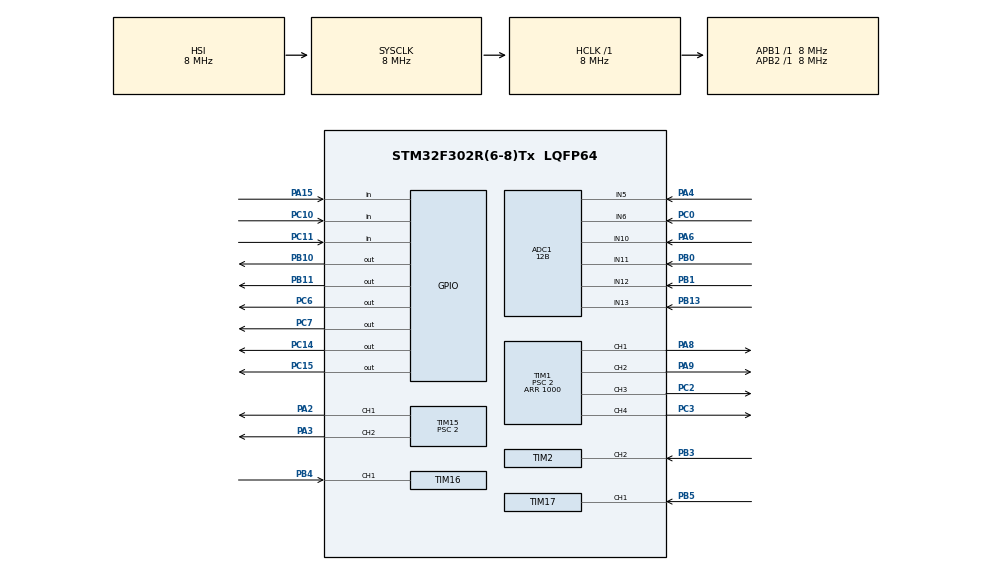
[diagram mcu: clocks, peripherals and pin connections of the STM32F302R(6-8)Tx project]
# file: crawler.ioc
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ADC1.Channel-0\#ChannelRegularConversion=ADC_CHANNEL_10
ADC1.Channel-10\#ChannelRegularConversion=ADC_CHANNEL_5
ADC1.Channel-11\#ChannelRegularConversion=ADC_CHANNEL_11
ADC1.Channel-12\#ChannelRegularConversion=ADC_CHANNEL_12
ADC1.Channel-13\#ChannelRegularConversion=ADC_CHANNEL_5
ADC1.Channel-14\#ChannelRegularConversion=ADC_CHANNEL_6
ADC1.Channel-15\#ChannelRegularConversion=ADC_CHANNEL_13
ADC1.Channel-6\#ChannelRegularConversion=ADC_CHANNEL_5
ADC1.Channel-7\#ChannelRegularConversion=ADC_CHANNEL_5
ADC1.Channel-8\#ChannelRegularConversion=ADC_CHANNEL_5
ADC1.Channel-9\#ChannelRegularConversion=ADC_CHANNEL_5
ADC1.ClockPrescaler=ADC_CLOCK_SYNC_PCLK_DIV4
ADC1.ContinuousConvMode=ENABLE
ADC1.DMAContinuousRequests=DISABLE
ADC1.DataAlign=ADC_DATAALIGN_RIGHT
ADC1.DiscontinuousConvMode=DISABLE
ADC1.EOCSelection=ADC_EOC_SINGLE_CONV
ADC1.EnableAnalogWatchDog1=false
ADC1.EnableAnalogWatchDog2=false
ADC1.EnableAnalogWatchDog3=false
ADC1.EnableInjectedConversion=ENABLE
ADC1.EnableRegularConversion=ENABLE
ADC1.ExternalTrigConv=ADC_SOFTWARE_START
ADC1.ExternalTrigConvEdge=ADC_EXTERNALTRIGCONVEDGE_NONE
ADC1.InjNumberOfConversion=0
ADC1.LowPowerAutoWait=DISABLE
ADC1.NbrOfConversion=6
ADC1.NbrOfConversionFlag=1
ADC1.Offset-0\#ChannelRegularConversion=0
ADC1.Offset-10\#ChannelRegularConversion=0
ADC1.Offset-11\#ChannelRegularConversion=0
ADC1.Offset-12\#ChannelRegularConversion=0
ADC1.Offset-13\#ChannelRegularConversion=0
ADC1.Offset-14\#ChannelRegularConversion=0
ADC1.Offset-15\#ChannelRegularConversion=0
ADC1.Offset-6\#ChannelRegularConversion=0
ADC1.Offset-7\#ChannelRegularConversion=0
ADC1.Offset-8\#ChannelRegularConversion=0
ADC1.Offset-9\#ChannelRegularConversion=0
ADC1.OffsetNumber-0\#ChannelRegularConversion=ADC_OFFSET_NONE
ADC1.OffsetNumber-10\#ChannelRegularConversion=ADC_OFFSET_NONE
ADC1.OffsetNumber-11\#ChannelRegularConversion=ADC_OFFSET_NONE
ADC1.OffsetNumber-12\#ChannelRegularConversion=ADC_OFFSET_NONE
ADC1.OffsetNumber-13\#ChannelRegularConversion=ADC_OFFSET_NONE
ADC1.OffsetNumber-14\#ChannelRegularConversion=ADC_OFFSET_NONE
ADC1.OffsetNumber-15\#ChannelRegularConversion=ADC_OFFSET_NONE
ADC1.OffsetNumber-6\#ChannelRegularConversion=ADC_OFFSET_NONE
ADC1.OffsetNumber-7\#ChannelRegularConversion=ADC_OFFSET_NONE
ADC1.OffsetNumber-8\#ChannelRegularConversion=ADC_OFFSET_NONE
ADC1.OffsetNumber-9\#ChannelRegularConversion=ADC_OFFSET_NONE
ADC1.Overrun=ADC_OVR_DATA_OVERWRITTEN
ADC1.Rank-0\#ChannelRegularConversion=1
ADC1.Rank-10\#ChannelRegularConversion=6
ADC1.Rank-11\#ChannelRegularConversion=2
ADC1.Rank-12\#ChannelRegularConversion=3
ADC1.Rank-13\#ChannelRegularConversion=4
ADC1.Rank-14\#ChannelRegularConversion=5
ADC1.Rank-15\#ChannelRegularConversion=6
ADC1.Rank-6\#ChannelRegularConversion=2
ADC1.Rank-7\#ChannelRegularConversion=3
ADC1.Rank-8\#ChannelRegularConversion=4
ADC1.Rank-9\#ChannelRegularConversion=5
ADC1.Resolution=ADC_RESOLUTION_12B
ADC1.SamplingTime-0\#ChannelRegularConversion=ADC_SAMPLETIME_1CYCLE_5
ADC1.SamplingTime-10\#ChannelRegularConversion=ADC_SAMPLETIME_1CYCLE_5
ADC1.SamplingTime-11\#ChannelRegularConversion=ADC_SAMPLETIME_1CYCLE_5
ADC1.SamplingTime-12\#ChannelRegularConversion=ADC_SAMPLETIME_1CYCLE_5
ADC1.SamplingTime-13\#ChannelRegularConversion=ADC_SAMPLETIME_1CYCLE_5
ADC1.SamplingTime-14\#ChannelRegularConversion=ADC_SAMPLETIME_1CYCLE_5
ADC1.SamplingTime-15\#ChannelRegularConversion=ADC_SAMPLETIME_1CYCLE_5
ADC1.SamplingTime-6\#ChannelRegularConversion=ADC_SAMPLETIME_1CYCLE_5
ADC1.SamplingTime-7\#ChannelRegularConversion=ADC_SAMPLETIME_1CYCLE_5
ADC1.SamplingTime-8\#ChannelRegularConversion=ADC_SAMPLETIME_1CYCLE_5
ADC1.SamplingTime-9\#ChannelRegularConversion=ADC_SAMPLETIME_1CYCLE_5
ADC1.ScanConvMode=ADC_SCAN_ENABLE
ADC1.master=1
Dma.ADC1.0.Direction=DMA_PERIPH_TO_MEMORY
Dma.ADC1.0.Instance=DMA1_Channel1
Dma.ADC1.0.MemDataAlignment=DMA_MDATAALIGN_HALFWORD
Dma.ADC1.0.MemInc=DMA_MINC_ENABLE
Dma.ADC1.0.Mode=DMA_NORMAL
Dma.ADC1.0.PeriphDataAlignment=DMA_PDATAALIGN_HALFWORD
Dma.ADC1.0.PeriphInc=DMA_PINC_DISABLE
Dma.ADC1.0.Priority=DMA_PRIORITY_LOW
Dma.Request0=ADC1
Mcu.Family=STM32F3
Mcu.Name=STM32F302R(6-8)Tx
Mcu.Package=LQFP64
NVIC.DMA1_Channel1_IRQn=true\:0\:0\:false\:false\:true\:false
NVIC.PriorityGroup=NVIC_PRIORITYGROUP_4
NVIC.TIM1_TRG_COM_TIM17_IRQn=true\:0\:0\:false\:false\:true\:true
NVIC.TIM1_UP_TIM16_IRQn=true\:0\:0\:false\:false\:true\:true
NVIC.TIM2_IRQn=true\:0\:0\:false\:false\:true\:true
PA15.Signal=GPIO_Input
PA2.Signal=S_TIM15_CH1
PA3.Signal=S_TIM15_CH2
PA4.Mode=IN5-Single-Ended
PA4.Signal=ADC1_IN5
PA6.Signal=ADCx_IN10
PA8.Signal=S_TIM1_CH1
PA9.Signal=S_TIM1_CH2
PB0.Mode=IN11-Single-Ended
PB0.Signal=ADC1_IN11
PB1.Mode=IN12-Single-Ended
PB1.Signal=ADC1_IN12
PB10.Signal=GPIO_Output
PB11.Signal=GPIO_Output
PB13.Mode=IN13-Single-Ended
PB13.Signal=ADC1_IN13
PB3.Signal=S_TIM2_CH2
PB4.Signal=S_TIM16_CH1
PB5.Signal=S_TIM17_CH1
PC0.Signal=ADCx_IN6
PC10.Signal=GPIO_Input
PC11.Signal=GPIO_Input
PC14\ -\ OSC32_IN.Signal=GPIO_Output
PC15\ -\ OSC32_OUT.Signal=GPIO_Output
PC2.Signal=S_TIM1_CH3
PC3.Signal=S_TIM1_CH4
PC6.Signal=GPIO_Output
PC7.Signal=GPIO_Output
PF0-OSC_IN.Mode=HSE-External-Oscillator
PF0-OSC_IN.Signal=RCC_OSC_IN
PF1-OSC_OUT.Mode=HSE-External-Oscillator
PF1-OSC_OUT.Signal=RCC_OSC_OUT
ProjectManager.HeapSize=0x200
ProjectManager.StackSize=0x400
ProjectManager.TargetToolchain=TrueSTUDIO
RCC.AHBFreq_Value=8000000
RCC.APB1Freq_Value=8000000
RCC.APB2Freq_Value=8000000
RCC.CortexFreq_Value=8000000
RCC.HSE_VALUE=8000000
RCC.HSI_VALUE=8000000
RCC.LSE_VALUE=32768
RCC.PLLMUL=RCC_PLL_MUL4
RCC.SYSCLKFreq_VALUE=8000000
RCC.USBFreq_Value=16000000
SH.ADCx_IN10.0=ADC1_IN10,IN10-Single-Ended
SH.ADCx_IN6.0=ADC1_IN6,IN6-Single-Ended
SH.S_TIM15_CH1.0=TIM15_CH1,PWM Generation1 CH1
SH.S_TIM15_CH2.0=TIM15_CH2,PWM Generation2 CH2
SH.S_TIM16_CH1.0=TIM16_CH1,Input_Capture1_from_TI1
SH.S_TIM17_CH1.0=TIM17_CH1,Input_Capture1_from_TI1
SH.S_TIM1_CH1.0=TIM1_CH1,PWM Generation1 CH1
SH.S_TIM1_CH2.0=TIM1_CH2,PWM Generation2 CH2
SH.S_TIM1_CH3.0=TIM1_CH3,PWM Generation3 CH3
SH.S_TIM1_CH4.0=TIM1_CH4,PWM Generation4 CH4
SH.S_TIM2_CH2.0=TIM2_CH2,Input_Capture2_from_TI2
TIM1.Channel-PWM\ Generation1\ CH1=TIM_CHANNEL_1
TIM1.Channel-PWM\ Generation2\ CH2=TIM_CHANNEL_2
TIM1.Channel-PWM\ Generation3\ CH3=TIM_CHANNEL_3
TIM1.Channel-PWM\ Generation4\ CH4=TIM_CHANNEL_4
TIM1.Period=1000
TIM1.Prescaler=2
TIM15.Channel-PWM\ Generation1\ CH1=TIM_CHANNEL_1
TIM15.Channel-PWM\ Generation2\ CH2=TIM_CHANNEL_2
TIM15.Period=1000
TIM15.Prescaler=2
TIM16.Channel=TIM_CHANNEL_1
TIM16.Period=0xFFFF
TIM16.Prescaler=10
TIM17.Channel=TIM_CHANNEL_1
TIM17.Period=0xFFFF
TIM17.Prescaler=10
TIM2.Channel-Input_Capture2_from_TI2=TIM_CHANNEL_2
TIM2.ICFilter_CH2=15
TIM2.Period=0xFFFF
TIM2.Prescaler=10
VP_TIM16_VS_ClockSourceINT.Mode=Enable_Timer
VP_TIM17_VS_ClockSourceINT.Mode=Enable_Timer
VP_TIM1_VS_ClockSourceINT.Mode=Internal
VP_TIM2_VS_ClockSourceINT.Mode=Internal
board=crawler

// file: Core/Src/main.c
/**
  ******************************************************************************
  * @file           : main.c
  * @brief          : Main program body
  ******************************************************************************
  ** This notice applies to any and all portions of this file
  * that are not between comment pairs USER CODE BEGIN and
  * USER CODE END. Other portions of this file, whether
  * inserted by the user or by software development tools
  * are owned by their respective copyright owners.
  *
  * COPYRIGHT(c) 2019 STMicroelectronics
  *
  * Redistribution and use in source and binary forms, with or without modification,
  * are permitted provided that the following conditions are met:
  *   1. Redistributions of source code must retain the above copyright notice,
  *      this list of conditions and the following disclaimer.
  *   2. Redistributions in binary form must reproduce the above copyright notice,
  *      this list of conditions and the following disclaimer in the documentation
  *      and/or other materials provided with the distribution.
  *   3. Neither the name of STMicroelectronics nor the names of its contributors
  *      may be used to endorse or promote products derived from this software
  *      without specific prior written permission.
  *
  * THIS SOFTWARE IS PROVIDED BY THE COPYRIGHT HOLDERS AND CONTRIBUTORS "AS IS"
  * AND ANY EXPRESS OR IMPLIED WARRANTIES, INCLUDING, BUT NOT LIMITED TO, THE
  * IMPLIED WARRANTIES OF MERCHANTABILITY AND FITNESS FOR A PARTICULAR PURPOSE ARE
  * DISCLAIMED. IN NO EVENT SHALL THE COPYRIGHT HOLDER OR CONTRIBUTORS BE LIABLE
  * FOR ANY DIRECT, INDIRECT, INCIDENTAL, SPECIAL, EXEMPLARY, OR CONSEQUENTIAL
  * DAMAGES (INCLUDING, BUT NOT LIMITED TO, PROCUREMENT OF SUBSTITUTE GOODS OR
  * SERVICES; LOSS OF USE, DATA, OR PROFITS; OR BUSINESS INTERRUPTION) HOWEVER
  * CAUSED AND ON ANY THEORY OF LIABILITY, WHETHER IN CONTRACT, STRICT LIABILITY,
  * OR TORT (INCLUDING NEGLIGENCE OR OTHERWISE) ARISING IN ANY WAY OUT OF THE USE
  * OF THIS SOFTWARE, EVEN IF ADVISED OF THE POSSIBILITY OF SUCH DAMAGE.
  *
  ******************************************************************************
  */
#include "main.h"
#include "stm32f3xx_hal.h"
#include <ADC_libF3.h>
#include <ENKPWM_libF3.h>
#include <PWM_libF3.h>

ADC_HandleTypeDef hadc1;
DMA_HandleTypeDef hdma_adc1;

TIM_HandleTypeDef htim1;
TIM_HandleTypeDef htim2;
TIM_HandleTypeDef htim15;
TIM_HandleTypeDef htim16;
TIM_HandleTypeDef htim17;

/* USER CODE BEGIN PV */
/* Private variables ---------------------------------------------------------*/
volatile uint32_t DMA_Stream[6];
volatile uint32_t Current[3];
/* USER CODE END PV */

void SystemClock_Config(void);
static void MX_GPIO_Init(void);
static void MX_DMA_Init(void);
static void MX_TIM1_Init(void);
static void MX_TIM15_Init(void);
static void MX_TIM2_Init(void);
static void MX_TIM16_Init(void);
static void MX_TIM17_Init(void);
static void MX_ADC1_Init(void);

void HAL_TIM_MspPostInit(TIM_HandleTypeDef *htim);

/* USER CODE BEGIN PFP */
/* Private function prototypes -----------------------------------------------*/

/* USER CODE END PFP */

int main(void)
{

  /* MCU Configuration----------------------------------------------------------*/

  /* Reset of all peripherals, Initializes the Flash interface and the Systick. */
  HAL_Init();

  /* Configure the system clock */
  SystemClock_Config();

  /* Initialize all configured peripherals */
  MX_GPIO_Init();
  MX_DMA_Init();
  MX_TIM1_Init();
  MX_TIM15_Init();
  MX_TIM2_Init();
  MX_TIM16_Init();
  MX_TIM17_Init();
  MX_ADC1_Init();

  HAL_ADC_Start_DMA(&hadc1, DMA_Stream, 6);
  /* USER CODE BEGIN 2 */
  PWM_Init();
  ENK_Init();
  StartMotors();
  SetPWM(-300);
  /* USER CODE END 2 */

  /* Infinite loop */
  /* USER CODE BEGIN WHILE */
  while (1)
  {
	  frequency_ret(abs_period_motor_1, abs_period_motor_2, abs_period_motor_3);

  /* USER CODE END WHILE */

  }

}

void SystemClock_Config(void)
{

  RCC_OscInitTypeDef RCC_OscInitStruct;
  RCC_ClkInitTypeDef RCC_ClkInitStruct;
  RCC_PeriphCLKInitTypeDef PeriphClkInit;

    /**Initializes the CPU, AHB and APB busses clocks
    */
  RCC_OscInitStruct.OscillatorType = RCC_OSCILLATORTYPE_HSI;
  RCC_OscInitStruct.HSIState = RCC_HSI_ON;
  RCC_OscInitStruct.HSICalibrationValue = 16;
  RCC_OscInitStruct.PLL.PLLState = RCC_PLL_NONE;
  if (HAL_RCC_OscConfig(&RCC_OscInitStruct) != HAL_OK)
  {
    _Error_Handler(__FILE__, __LINE__);
  }

    /**Initializes the CPU, AHB and APB busses clocks
    */
  RCC_ClkInitStruct.ClockType = RCC_CLOCKTYPE_HCLK|RCC_CLOCKTYPE_SYSCLK
                              |RCC_CLOCKTYPE_PCLK1|RCC_CLOCKTYPE_PCLK2;
  RCC_ClkInitStruct.SYSCLKSource = RCC_SYSCLKSOURCE_HSI;
  RCC_ClkInitStruct.AHBCLKDivider = RCC_SYSCLK_DIV1;
  RCC_ClkInitStruct.APB1CLKDivider = RCC_HCLK_DIV1;
  RCC_ClkInitStruct.APB2CLKDivider = RCC_HCLK_DIV1;

  if (HAL_RCC_ClockConfig(&RCC_ClkInitStruct, FLASH_LATENCY_0) != HAL_OK)
  {
    _Error_Handler(__FILE__, __LINE__);
  }

  PeriphClkInit.PeriphClockSelection = RCC_PERIPHCLK_TIM1|RCC_PERIPHCLK_TIM15
                              |RCC_PERIPHCLK_TIM16|RCC_PERIPHCLK_TIM17;
  PeriphClkInit.Tim1ClockSelection = RCC_TIM1CLK_HCLK;
  PeriphClkInit.Tim15ClockSelection = RCC_TIM15CLK_HCLK;
  PeriphClkInit.Tim16ClockSelection = RCC_TIM16CLK_HCLK;
  PeriphClkInit.Tim17ClockSelection = RCC_TIM17CLK_HCLK;
  if (HAL_RCCEx_PeriphCLKConfig(&PeriphClkInit) != HAL_OK)
  {
    _Error_Handler(__FILE__, __LINE__);
  }

    /**Configure the Systick interrupt time
    */
  HAL_SYSTICK_Config(HAL_RCC_GetHCLKFreq()/1000);

    /**Configure the Systick
    */
  HAL_SYSTICK_CLKSourceConfig(SYSTICK_CLKSOURCE_HCLK);

  /* SysTick_IRQn interrupt configuration */
  HAL_NVIC_SetPriority(SysTick_IRQn, 0, 0);
}

/* ADC1 init function */
static void MX_ADC1_Init(void)
{

  ADC_ChannelConfTypeDef sConfig;

    /**Common config
    */
  hadc1.Instance = ADC1;
  hadc1.Init.ClockPrescaler = ADC_CLOCK_SYNC_PCLK_DIV4;
  hadc1.Init.Resolution = ADC_RESOLUTION_12B;
  hadc1.Init.ScanConvMode = ADC_SCAN_ENABLE;
  hadc1.Init.ContinuousConvMode = ENABLE;
  hadc1.Init.DiscontinuousConvMode = DISABLE;
  hadc1.Init.ExternalTrigConvEdge = ADC_EXTERNALTRIGCONVEDGE_NONE;
  hadc1.Init.ExternalTrigConv = ADC_SOFTWARE_START;
  hadc1.Init.DataAlign = ADC_DATAALIGN_RIGHT;
  hadc1.Init.NbrOfConversion = 6;
  hadc1.Init.DMAContinuousRequests = DISABLE;
  hadc1.Init.EOCSelection = ADC_EOC_SINGLE_CONV;
  hadc1.Init.LowPowerAutoWait = DISABLE;
  hadc1.Init.Overrun = ADC_OVR_DATA_OVERWRITTEN;
  if (HAL_ADC_Init(&hadc1) != HAL_OK)
  {
    _Error_Handler(__FILE__, __LINE__);
  }

    /**Configure Regular Channel
    */
  sConfig.Channel = ADC_CHANNEL_10;
  sConfig.Rank = ADC_REGULAR_RANK_1;
  sConfig.SingleDiff = ADC_SINGLE_ENDED;
  sConfig.SamplingTime = ADC_SAMPLETIME_1CYCLE_5;
  sConfig.OffsetNumber = ADC_OFFSET_NONE;
  sConfig.Offset = 0;
  if (HAL_ADC_ConfigChannel(&hadc1, &sConfig) != HAL_OK)
  {
    _Error_Handler(__FILE__, __LINE__);
  }

    /**Configure Regular Channel
    */
  sConfig.Channel = ADC_CHANNEL_11;
  sConfig.Rank = ADC_REGULAR_RANK_2;
  if (HAL_ADC_ConfigChannel(&hadc1, &sConfig) != HAL_OK)
  {
    _Error_Handler(__FILE__, __LINE__);
  }

    /**Configure Regular Channel
    */
  sConfig.Channel = ADC_CHANNEL_12;
  sConfig.Rank = ADC_REGULAR_RANK_3;
  if (HAL_ADC_ConfigChannel(&hadc1, &sConfig) != HAL_OK)
  {
    _Error_Handler(__FILE__, __LINE__);
  }

    /**Configure Regular Channel
    */
  sConfig.Channel = ADC_CHANNEL_5;
  sConfig.Rank = ADC_REGULAR_RANK_4;
  if (HAL_ADC_ConfigChannel(&hadc1, &sConfig) != HAL_OK)
  {
    _Error_Handler(__FILE__, __LINE__);
  }

    /**Configure Regular Channel
    */
  sConfig.Channel = ADC_CHANNEL_6;
  sConfig.Rank = ADC_REGULAR_RANK_5;
  if (HAL_ADC_ConfigChannel(&hadc1, &sConfig) != HAL_OK)
  {
    _Error_Handler(__FILE__, __LINE__);
  }

    /**Configure Regular Channel
    */
  sConfig.Channel = ADC_CHANNEL_13;
  sConfig.Rank = ADC_REGULAR_RANK_6;
  if (HAL_ADC_ConfigChannel(&hadc1, &sConfig) != HAL_OK)
  {
    _Error_Handler(__FILE__, __LINE__);
  }

}

/* TIM1 init function */
static void MX_TIM1_Init(void)
{

  TIM_ClockConfigTypeDef sClockSourceConfig;
  TIM_MasterConfigTypeDef sMasterConfig;
  TIM_OC_InitTypeDef sConfigOC;
  TIM_BreakDeadTimeConfigTypeDef sBreakDeadTimeConfig;

  htim1.Instance = TIM1;
  htim1.Init.Prescaler = 2;
  htim1.Init.CounterMode = TIM_COUNTERMODE_UP;
  htim1.Init.Period = 1000;
  htim1.Init.ClockDivision = TIM_CLOCKDIVISION_DIV1;
  htim1.Init.RepetitionCounter = 0;
  htim1.Init.AutoReloadPreload = TIM_AUTORELOAD_PRELOAD_DISABLE;
  if (HAL_TIM_Base_Init(&htim1) != HAL_OK)
  {
    _Error_Handler(__FILE__, __LINE__);
  }

  sClockSourceConfig.ClockSource = TIM_CLOCKSOURCE_INTERNAL;
  if (HAL_TIM_ConfigClockSource(&htim1, &sClockSourceConfig) != HAL_OK)
  {
    _Error_Handler(__FILE__, __LINE__);
  }

  if (HAL_TIM_PWM_Init(&htim1) != HAL_OK)
  {
    _Error_Handler(__FILE__, __LINE__);
  }

  sMasterConfig.MasterOutputTrigger = TIM_TRGO_RESET;
  sMasterConfig.MasterOutputTrigger2 = TIM_TRGO2_RESET;
  sMasterConfig.MasterSlaveMode = TIM_MASTERSLAVEMODE_DISABLE;
  if (HAL_TIMEx_MasterConfigSynchronization(&htim1, &sMasterConfig) != HAL_OK)
  {
    _Error_Handler(__FILE__, __LINE__);
  }

  sConfigOC.OCMode = TIM_OCMODE_PWM1;
  sConfigOC.Pulse = 0;
  sConfigOC.OCPolarity = TIM_OCPOLARITY_HIGH;
  sConfigOC.OCNPolarity = TIM_OCNPOLARITY_HIGH;
  sConfigOC.OCFastMode = TIM_OCFAST_DISABLE;
  sConfigOC.OCIdleState = TIM_OCIDLESTATE_RESET;
  sConfigOC.OCNIdleState = TIM_OCNIDLESTATE_RESET;
  if (HAL_TIM_PWM_ConfigChannel(&htim1, &sConfigOC, TIM_CHANNEL_1) != HAL_OK)
  {
    _Error_Handler(__FILE__, __LINE__);
  }

  if (HAL_TIM_PWM_ConfigChannel(&htim1, &sConfigOC, TIM_CHANNEL_2) != HAL_OK)
  {
    _Error_Handler(__FILE__, __LINE__);
  }

  if (HAL_TIM_PWM_ConfigChannel(&htim1, &sConfigOC, TIM_CHANNEL_3) != HAL_OK)
  {
    _Error_Handler(__FILE__, __LINE__);
  }

  if (HAL_TIM_PWM_ConfigChannel(&htim1, &sConfigOC, TIM_CHANNEL_4) != HAL_OK)
  {
    _Error_Handler(__FILE__, __LINE__);
  }

  sBreakDeadTimeConfig.OffStateRunMode = TIM_OSSR_DISABLE;
  sBreakDeadTimeConfig.OffStateIDLEMode = TIM_OSSI_DISABLE;
  sBreakDeadTimeConfig.LockLevel = TIM_LOCKLEVEL_OFF;
  sBreakDeadTimeConfig.DeadTime = 0;
  sBreakDeadTimeConfig.BreakState = TIM_BREAK_DISABLE;
  sBreakDeadTimeConfig.BreakPolarity = TIM_BREAKPOLARITY_HIGH;
  sBreakDeadTimeConfig.BreakFilter = 0;
  sBreakDeadTimeConfig.Break2State = TIM_BREAK2_DISABLE;
  sBreakDeadTimeConfig.Break2Polarity = TIM_BREAK2POLARITY_HIGH;
  sBreakDeadTimeConfig.Break2Filter = 0;
  sBreakDeadTimeConfig.AutomaticOutput = TIM_AUTOMATICOUTPUT_DISABLE;
  if (HAL_TIMEx_ConfigBreakDeadTime(&htim1, &sBreakDeadTimeConfig) != HAL_OK)
  {
    _Error_Handler(__FILE__, __LINE__);
  }

  HAL_TIM_MspPostInit(&htim1);

}

/* TIM2 init function */
static void MX_TIM2_Init(void)
{

  TIM_ClockConfigTypeDef sClockSourceConfig;
  TIM_MasterConfigTypeDef sMasterConfig;
  TIM_IC_InitTypeDef sConfigIC;

  htim2.Instance = TIM2;
  htim2.Init.Prescaler = 10;
  htim2.Init.CounterMode = TIM_COUNTERMODE_UP;
  htim2.Init.Period = 0xFFFF;
  htim2.Init.ClockDivision = TIM_CLOCKDIVISION_DIV1;
  htim2.Init.AutoReloadPreload = TIM_AUTORELOAD_PRELOAD_DISABLE;
  if (HAL_TIM_Base_Init(&htim2) != HAL_OK)
  {
    _Error_Handler(__FILE__, __LINE__);
  }

  sClockSourceConfig.ClockSource = TIM_CLOCKSOURCE_INTERNAL;
  if (HAL_TIM_ConfigClockSource(&htim2, &sClockSourceConfig) != HAL_OK)
  {
    _Error_Handler(__FILE__, __LINE__);
  }

  if (HAL_TIM_IC_Init(&htim2) != HAL_OK)
  {
    _Error_Handler(__FILE__, __LINE__);
  }

  sMasterConfig.MasterOutputTrigger = TIM_TRGO_RESET;
  sMasterConfig.MasterSlaveMode = TIM_MASTERSLAVEMODE_DISABLE;
  if (HAL_TIMEx_MasterConfigSynchronization(&htim2, &sMasterConfig) != HAL_OK)
  {
    _Error_Handler(__FILE__, __LINE__);
  }

  sConfigIC.ICPolarity = TIM_INPUTCHANNELPOLARITY_RISING;
  sConfigIC.ICSelection = TIM_ICSELECTION_DIRECTTI;
  sConfigIC.ICPrescaler = TIM_ICPSC_DIV1;
  sConfigIC.ICFilter = 15;
  if (HAL_TIM_IC_ConfigChannel(&htim2, &sConfigIC, TIM_CHANNEL_2) != HAL_OK)
  {
    _Error_Handler(__FILE__, __LINE__);
  }

}

/* TIM15 init function */
static void MX_TIM15_Init(void)
{

  TIM_MasterConfigTypeDef sMasterConfig;
  TIM_OC_InitTypeDef sConfigOC;
  TIM_BreakDeadTimeConfigTypeDef sBreakDeadTimeConfig;

  htim15.Instance = TIM15;
  htim15.Init.Prescaler = 2;
  htim15.Init.CounterMode = TIM_COUNTERMODE_UP;
  htim15.Init.Period = 1000;
  htim15.Init.ClockDivision = TIM_CLOCKDIVISION_DIV1;
  htim15.Init.RepetitionCounter = 0;
  htim15.Init.AutoReloadPreload = TIM_AUTORELOAD_PRELOAD_DISABLE;
  if (HAL_TIM_PWM_Init(&htim15) != HAL_OK)
  {
    _Error_Handler(__FILE__, __LINE__);
  }

  sMasterConfig.MasterOutputTrigger = TIM_TRGO_RESET;
  sMasterConfig.MasterSlaveMode = TIM_MASTERSLAVEMODE_DISABLE;
  if (HAL_TIMEx_MasterConfigSynchronization(&htim15, &sMasterConfig) != HAL_OK)
  {
    _Error_Handler(__FILE__, __LINE__);
  }

  sConfigOC.OCMode = TIM_OCMODE_PWM1;
  sConfigOC.Pulse = 0;
  sConfigOC.OCPolarity = TIM_OCPOLARITY_HIGH;
  sConfigOC.OCNPolarity = TIM_OCNPOLARITY_HIGH;
  sConfigOC.OCFastMode = TIM_OCFAST_DISABLE;
  sConfigOC.OCIdleState = TIM_OCIDLESTATE_RESET;
  sConfigOC.OCNIdleState = TIM_OCNIDLESTATE_RESET;
  if (HAL_TIM_PWM_ConfigChannel(&htim15, &sConfigOC, TIM_CHANNEL_1) != HAL_OK)
  {
    _Error_Handler(__FILE__, __LINE__);
  }

  if (HAL_TIM_PWM_ConfigChannel(&htim15, &sConfigOC, TIM_CHANNEL_2) != HAL_OK)
  {
    _Error_Handler(__FILE__, __LINE__);
  }

  sBreakDeadTimeConfig.OffStateRunMode = TIM_OSSR_DISABLE;
  sBreakDeadTimeConfig.OffStateIDLEMode = TIM_OSSI_DISABLE;
  sBreakDeadTimeConfig.LockLevel = TIM_LOCKLEVEL_OFF;
  sBreakDeadTimeConfig.DeadTime = 0;
  sBreakDeadTimeConfig.BreakState = TIM_BREAK_DISABLE;
  sBreakDeadTimeConfig.BreakPolarity = TIM_BREAKPOLARITY_HIGH;
  sBreakDeadTimeConfig.BreakFilter = 0;
  sBreakDeadTimeConfig.AutomaticOutput = TIM_AUTOMATICOUTPUT_DISABLE;
  if (HAL_TIMEx_ConfigBreakDeadTime(&htim15, &sBreakDeadTimeConfig) != HAL_OK)
  {
    _Error_Handler(__FILE__, __LINE__);
  }

  HAL_TIM_MspPostInit(&htim15);

}

/* TIM16 init function */
static void MX_TIM16_Init(void)
{

  TIM_IC_InitTypeDef sConfigIC;

  htim16.Instance = TIM16;
  htim16.Init.Prescaler = 10;
  htim16.Init.CounterMode = TIM_COUNTERMODE_UP;
  htim16.Init.Period = 0xFFFF;
  htim16.Init.ClockDivision = TIM_CLOCKDIVISION_DIV1;
  htim16.Init.RepetitionCounter = 0;
  htim16.Init.AutoReloadPreload = TIM_AUTORELOAD_PRELOAD_DISABLE;
  if (HAL_TIM_Base_Init(&htim16) != HAL_OK)
  {
    _Error_Handler(__FILE__, __LINE__);
  }

  if (HAL_TIM_IC_Init(&htim16) != HAL_OK)
  {
    _Error_Handler(__FILE__, __LINE__);
  }

  sConfigIC.ICPolarity = TIM_INPUTCHANNELPOLARITY_RISING;
  sConfigIC.ICSelection = TIM_ICSELECTION_DIRECTTI;
  sConfigIC.ICPrescaler = TIM_ICPSC_DIV1;
  sConfigIC.ICFilter = 0;
  if (HAL_TIM_IC_ConfigChannel(&htim16, &sConfigIC, TIM_CHANNEL_1) != HAL_OK)
  {
    _Error_Handler(__FILE__, __LINE__);
  }

}

/* TIM17 init function */
static void MX_TIM17_Init(void)
{

  TIM_IC_InitTypeDef sConfigIC;

  htim17.Instance = TIM17;
  htim17.Init.Prescaler = 10;
  htim17.Init.CounterMode = TIM_COUNTERMODE_UP;
  htim17.Init.Period = 0xFFFF;
  htim17.Init.ClockDivision = TIM_CLOCKDIVISION_DIV1;
  htim17.Init.RepetitionCounter = 0;
  htim17.Init.AutoReloadPreload = TIM_AUTORELOAD_PRELOAD_DISABLE;
  if (HAL_TIM_Base_Init(&htim17) != HAL_OK)
  {
    _Error_Handler(__FILE__, __LINE__);
  }

  if (HAL_TIM_IC_Init(&htim17) != HAL_OK)
  {
    _Error_Handler(__FILE__, __LINE__);
  }

  sConfigIC.ICPolarity = TIM_INPUTCHANNELPOLARITY_RISING;
  sConfigIC.ICSelection = TIM_ICSELECTION_DIRECTTI;
  sConfigIC.ICPrescaler = TIM_ICPSC_DIV1;
  sConfigIC.ICFilter = 0;
  if (HAL_TIM_IC_ConfigChannel(&htim17, &sConfigIC, TIM_CHANNEL_1) != HAL_OK)
  {
    _Error_Handler(__FILE__, __LINE__);
  }

}

static void MX_DMA_Init(void)
{
  /* DMA controller clock enable */
  __HAL_RCC_DMA1_CLK_ENABLE();

  /* DMA interrupt init */
  /* DMA1_Channel1_IRQn interrupt configuration */
  HAL_NVIC_SetPriority(DMA1_Channel1_IRQn, 0, 0);
  HAL_NVIC_EnableIRQ(DMA1_Channel1_IRQn);

}

/** Configure pins as
        * Analog
        * Input
        * Output
        * EVENT_OUT
        * EXTI
*/
static void MX_GPIO_Init(void)
{

  GPIO_InitTypeDef GPIO_InitStruct;

  /* GPIO Ports Clock Enable */
  __HAL_RCC_GPIOC_CLK_ENABLE();
  __HAL_RCC_GPIOF_CLK_ENABLE();
  __HAL_RCC_GPIOA_CLK_ENABLE();
  __HAL_RCC_GPIOB_CLK_ENABLE();

  /*Configure GPIO pin Output Level */
  HAL_GPIO_WritePin(GPIOC, GPIO_PIN_14|GPIO_PIN_15|GPIO_PIN_6|GPIO_PIN_7, GPIO_PIN_RESET);

  /*Configure GPIO pin Output Level */
  HAL_GPIO_WritePin(GPIOB, GPIO_PIN_10|GPIO_PIN_11, GPIO_PIN_RESET);

  /*Configure GPIO pins : PC14 PC15 PC6 PC7 */
  GPIO_InitStruct.Pin = GPIO_PIN_14|GPIO_PIN_15|GPIO_PIN_6|GPIO_PIN_7;
  GPIO_InitStruct.Mode = GPIO_MODE_OUTPUT_PP;
  GPIO_InitStruct.Pull = GPIO_NOPULL;
  GPIO_InitStruct.Speed = GPIO_SPEED_FREQ_LOW;
  HAL_GPIO_Init(GPIOC, &GPIO_InitStruct);

  /*Configure GPIO pins : PB10 PB11 */
  GPIO_InitStruct.Pin = GPIO_PIN_10|GPIO_PIN_11;
  GPIO_InitStruct.Mode = GPIO_MODE_OUTPUT_PP;
  GPIO_InitStruct.Pull = GPIO_NOPULL;
  GPIO_InitStruct.Speed = GPIO_SPEED_FREQ_LOW;
  HAL_GPIO_Init(GPIOB, &GPIO_InitStruct);

  /*Configure GPIO pin : PA15 */
  GPIO_InitStruct.Pin = GPIO_PIN_15;
  GPIO_InitStruct.Mode = GPIO_MODE_INPUT;
  GPIO_InitStruct.Pull = GPIO_NOPULL;
  HAL_GPIO_Init(GPIOA, &GPIO_InitStruct);

  /*Configure GPIO pins : PC10 PC11 */
  GPIO_InitStruct.Pin = GPIO_PIN_10|GPIO_PIN_11;
  GPIO_InitStruct.Mode = GPIO_MODE_INPUT;
  GPIO_InitStruct.Pull = GPIO_NOPULL;
  HAL_GPIO_Init(GPIOC, &GPIO_InitStruct);

}

void _Error_Handler(char *file, int line)
{
  while(1)
  {
  }
}

/************************ (C) COPYRIGHT STMicroelectronics *****END OF FILE****/
